VERSION ""

NS_ :

BS_:

BU_: SFUS ECU DASH TEL

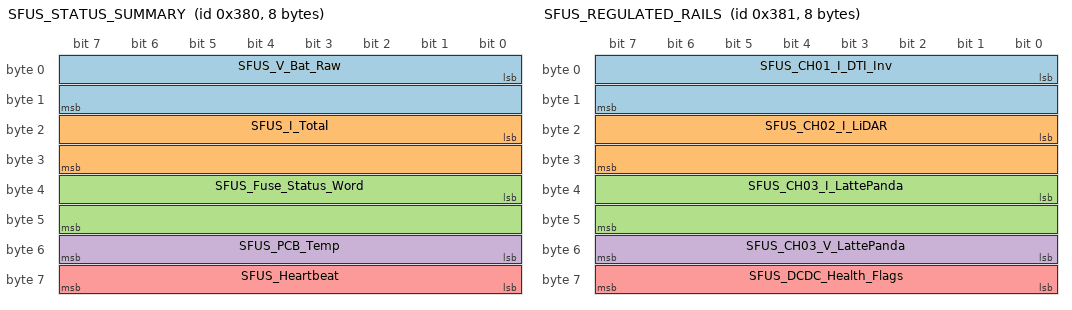
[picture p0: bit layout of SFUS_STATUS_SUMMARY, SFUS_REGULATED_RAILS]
BO_ 896 SFUS_STATUS_SUMMARY: 8 SFUS
 SG_ SFUS_V_Bat_Raw : 0|16@1+ (0.01,0) [0|65.535] "V" ECU,TEL
 SG_ SFUS_I_Total : 16|16@1+ (0.05,0) [0|50] "A" ECU,TEL
 SG_ SFUS_Fuse_Status_Word : 32|16@1+ (1,0) [0|65535] "" ECU,TEL,DASH
 SG_ SFUS_PCB_Temp : 48|8@1- (1,0) [-40|125] "degC" ECU,TEL
 SG_ SFUS_Heartbeat : 56|8@1+ (1,0) [0|255] "" ECU,TEL

BO_ 897 SFUS_REGULATED_RAILS: 8 SFUS
 SG_ SFUS_CH01_I_DTI_Inv : 0|16@1+ (1,0) [0|5000] "mA" ECU,TEL
 SG_ SFUS_CH02_I_LiDAR : 16|16@1+ (1,0) [0|3000] "mA" ECU,TEL
 SG_ SFUS_CH03_I_LattePanda : 32|16@1+ (2,0) [0|10000] "mA" ECU,TEL
 SG_ SFUS_CH03_V_LattePanda : 48|8@1+ (0.1,0) [15|25] "V" ECU,TEL
 SG_ SFUS_DCDC_Health_Flags : 56|8@1+ (1,0) [0|255] "" ECU,TEL

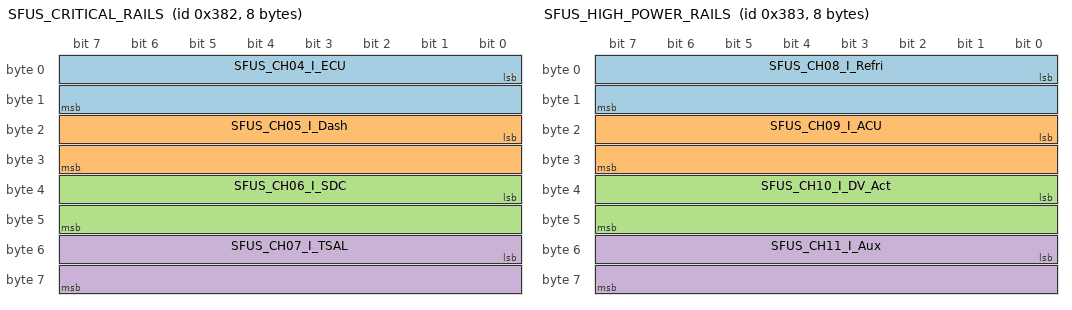
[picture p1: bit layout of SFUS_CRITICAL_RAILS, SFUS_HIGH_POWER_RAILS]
BO_ 898 SFUS_CRITICAL_RAILS: 8 SFUS
 SG_ SFUS_CH04_I_ECU : 0|16@1+ (1,0) [0|6000] "mA" ECU,TEL
 SG_ SFUS_CH05_I_Dash : 16|16@1+ (1,0) [0|6000] "mA" ECU,TEL
 SG_ SFUS_CH06_I_SDC : 32|16@1+ (1,0) [0|5000] "mA" ECU,TEL
 SG_ SFUS_CH07_I_TSAL : 48|16@1+ (1,0) [0|5000] "mA" ECU,TEL

BO_ 899 SFUS_HIGH_POWER_RAILS: 8 SFUS
 SG_ SFUS_CH08_I_Refri : 0|16@1+ (10,0) [0|20000] "mA" ECU,TEL
 SG_ SFUS_CH09_I_ACU : 16|16@1+ (1,0) [0|6000] "mA" ECU,TEL
 SG_ SFUS_CH10_I_DV_Act : 32|16@1+ (5,0) [0|15000] "mA" ECU,TEL
 SG_ SFUS_CH11_I_Aux : 48|16@1+ (1,0) [0|6000] "mA" ECU,TEL

CM_ BO_ 896 "Smart Fusibles - 0x380 Summary status, raw input voltage, total current and blown fuse word (50 Hz)";
CM_ BO_ 897 "Smart Fusibles - 0x381 Dedicated regulated rails telemetry (DTI 12V, LiDAR 12V, LattePanda 19V) (10 Hz)";
CM_ BO_ 898 "Smart Fusibles - 0x382 Critical vehicle control rails telemetry (ECU, Dash, SDC, TSAL) (10 Hz)";
CM_ BO_ 899 "Smart Fusibles - 0x383 High power and auxiliary rails telemetry (Cooling, ACU, Driverless, Aux) (10 Hz)";

BA_DEF_ BO_ "GenMsgCycleTime" INT 0 50000;
BA_DEF_ "BusType" STRING ;
BA_DEF_DEF_ "BusType" "CAN";
BA_DEF_DEF_ "GenMsgCycleTime" 100;

BA_ "GenMsgCycleTime" BO_ 896 20;
